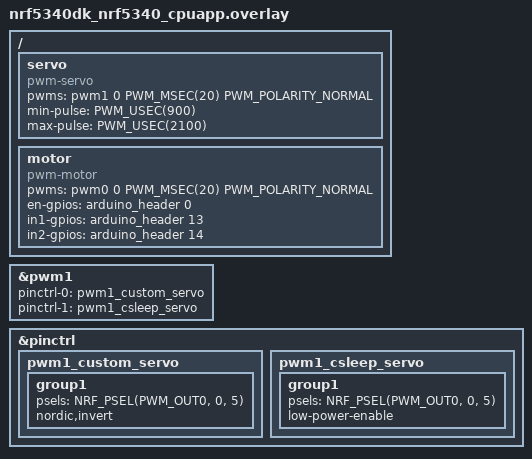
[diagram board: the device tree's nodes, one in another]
/ {
    servo: servo {
        compatible = "pwm-servo";
        pwms = <&pwm1 0 PWM_MSEC(20) PWM_POLARITY_NORMAL>;
        min-pulse = <PWM_USEC(900)>;
        max-pulse = <PWM_USEC(2100)>;
    };

    motor: motor {
        compatible = "pwm-motor";
        pwms = <&pwm0 0 PWM_MSEC(20) PWM_POLARITY_NORMAL>;
        en-gpios = <&arduino_header 0 GPIO_ACTIVE_HIGH>;
        in1-gpios = <&arduino_header 13 GPIO_ACTIVE_HIGH>;
        in2-gpios = <&arduino_header 14 GPIO_ACTIVE_HIGH>;
    };
};

&pwm1 {
    status = "okay";
    pinctrl-0 = <&pwm1_custom_servo>;
    pinctrl-1 = <&pwm1_csleep_servo>;
    pinctrl-names = "default", "sleep";
};

&pinctrl {
    pwm1_custom_servo: pwm1_custom_servo {
        group1 {
            psels = <NRF_PSEL(PWM_OUT0, 0, 5)>;
            nordic,invert;
        };
    };

    pwm1_csleep_servo: pwm1_csleep_servo {
        group1 {
            psels = <NRF_PSEL(PWM_OUT0, 0, 5)>;
            low-power-enable;
        };
    };
};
